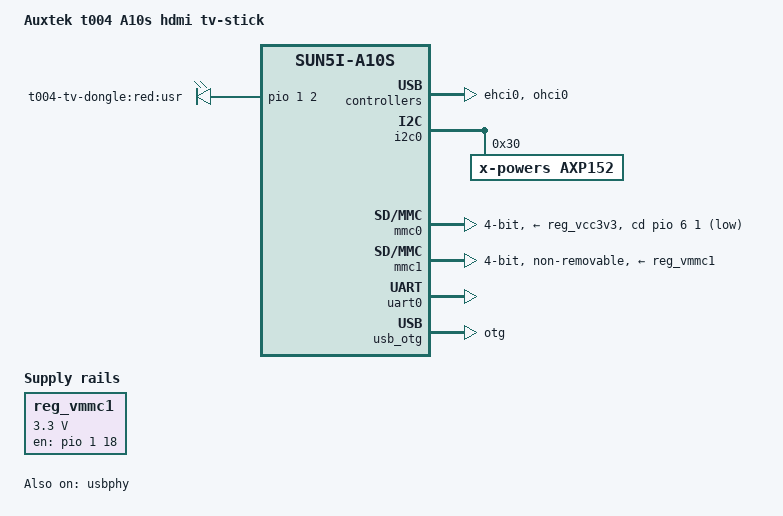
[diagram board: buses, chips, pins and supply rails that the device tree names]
/dts-v1/;
#include "sun5i-a10s.dtsi"
#include "sunxi-common-regulators.dtsi"
#include <dt-bindings/gpio/gpio.h>
/ {
	model = "Auxtek t004 A10s hdmi tv-stick";
	compatible = "allwinner,auxtek-t004", "allwinner,sun5i-a10s";
	aliases {
		serial0 = &uart0;
	};
	chosen {
		stdout-path = "serial0:115200n8";
	};
	leds {
		compatible = "gpio-leds";
		pinctrl-names = "default";
		pinctrl-0 = <&led_pins_t004>;
		led {
			label = "t004-tv-dongle:red:usr";
			gpios = <&pio 1 2 GPIO_ACTIVE_HIGH>;  
			default-state = "on";
		};
	};
	reg_vmmc1: vmmc1 {
		compatible = "regulator-fixed";
		regulator-name = "vmmc1";
		regulator-min-microvolt = <3300000>;
		regulator-max-microvolt = <3300000>;
		enable-active-high;
		gpio = <&pio 1 18 GPIO_ACTIVE_HIGH>;  
	};
};
&ehci0 {
	status = "okay";
};
&i2c0 {
	status = "okay";
	axp152: pmic@30 {
		compatible = "x-powers,axp152";
		reg = <0x30>;
		interrupts = <0>;
		interrupt-controller;
		#interrupt-cells = <1>;
	};
};
&mmc0 {
	vmmc-supply = <&reg_vcc3v3>;
	bus-width = <4>;
	cd-gpios = <&pio 6 1 GPIO_ACTIVE_LOW>;  
	status = "okay";
};
&mmc1 {
	vmmc-supply = <&reg_vmmc1>;
	bus-width = <4>;
	non-removable;
	cap-sdio-irq;
	status = "okay";
};
&ohci0 {
	status = "okay";
};
&otg_sram {
	status = "okay";
};
&pio {
	led_pins_t004: led-pin {
		pins = "PB2";
		function = "gpio_out";
		drive-strength = <20>;
	};
};
&reg_usb1_vbus {
	gpio = <&pio 6 13 GPIO_ACTIVE_HIGH>;  
	status = "okay";
};
&uart0 {
	pinctrl-names = "default";
	pinctrl-0 = <&uart0_pb_pins>;
	status = "okay";
};
&usb_otg {
	dr_mode = "otg";
	status = "okay";
};
&usbphy {
	usb0_id_det-gpios = <&pio 6 12 (GPIO_ACTIVE_HIGH | GPIO_PULL_UP)>;  
	usb1_vbus-supply = <&reg_usb1_vbus>;
	status = "okay";
};
